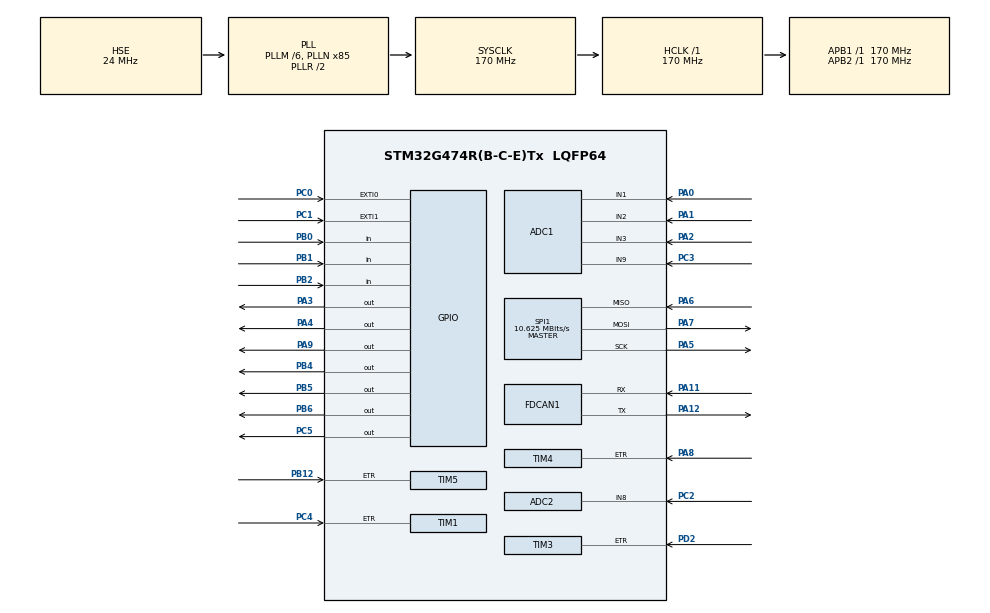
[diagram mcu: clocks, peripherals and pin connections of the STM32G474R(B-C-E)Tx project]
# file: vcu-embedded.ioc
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ADC1.Channel-0\#ChannelRegularConversion=ADC_CHANNEL_1
ADC1.NbrOfConversionFlag=1
ADC1.OffsetNumber-0\#ChannelRegularConversion=ADC_OFFSET_NONE
ADC1.Rank-0\#ChannelRegularConversion=1
ADC1.SamplingTime-0\#ChannelRegularConversion=ADC_SAMPLETIME_2CYCLES_5
ADC1.master=1
ADC2.Channel-1\#ChannelRegularConversion=ADC_CHANNEL_8
ADC2.NbrOfConversionFlag=1
ADC2.OffsetNumber-1\#ChannelRegularConversion=ADC_OFFSET_NONE
ADC2.Rank-1\#ChannelRegularConversion=1
ADC2.SamplingTime-1\#ChannelRegularConversion=ADC_SAMPLETIME_2CYCLES_5
FDCAN1.CalculateBaudRateNominal=500000
FDCAN1.CalculateTimeBitNominal=2000
FDCAN1.CalculateTimeQuantumNominal=83.33333333333333
FDCAN1.DataPrescaler=2
FDCAN1.DataTimeSeg1=12
FDCAN1.DataTimeSeg2=11
FDCAN1.NominalPrescaler=2
FDCAN1.NominalTimeSeg1=20
FDCAN1.NominalTimeSeg2=3
FREERTOS.Tasks01=gps,24,128,StartDefaultTask,Default,NULL,Dynamic,NULL,NULL
FREERTOS.configMAX_TASK_NAME_LEN=32
FREERTOS.configTOTAL_HEAP_SIZE=8000
Mcu.Family=STM32G4
Mcu.Name=STM32G474R(B-C-E)Tx
Mcu.Package=LQFP64
NVIC.PriorityGroup=NVIC_PRIORITYGROUP_4
NVIC.TIM6_DAC_IRQn=true\:15\:0\:false\:false\:true\:false\:false\:true\:true
NVIC.TimeBase=TIM6_DAC_IRQn
NVIC.TimeBaseIP=TIM6
PA0.Mode=IN1-Single-Ended
PA0.Signal=ADC1_IN1
PA1.Mode=IN2-Single-Ended
PA1.Signal=ADC1_IN2
PA11.Mode=FDCAN_Activate
PA11.Signal=FDCAN1_RX
PA12.Mode=FDCAN_Activate
PA12.Signal=FDCAN1_TX
PA13.Mode=Trace_Asynchronous_SW
PA13.Signal=SYS_JTMS-SWDIO
PA14.Mode=Trace_Asynchronous_SW
PA14.Signal=SYS_JTCK-SWCLK
PA2.Mode=IN3-Single-Ended
PA2.Signal=ADC1_IN3
PA3.Signal=GPIO_Output
PA4.Signal=GPIO_Output
PA5.Mode=Full_Duplex_Master
PA5.Signal=SPI1_SCK
PA6.Mode=Full_Duplex_Master
PA6.Signal=SPI1_MISO
PA7.Mode=Full_Duplex_Master
PA7.Signal=SPI1_MOSI
PA8.Signal=S_TIM4_ETR
PA9.Signal=GPIO_Output
PB0.Signal=GPIO_Input
PB1.Signal=GPIO_Input
PB12.Signal=S_TIM5_ETR
PB2.Signal=GPIO_Input
PB3.Mode=Trace_Asynchronous_SW
PB3.Signal=SYS_JTDO-SWO
PB4.Signal=GPIO_Output
PB5.Signal=GPIO_Output
PB6.Signal=GPIO_Output
PC0.Signal=GPXTI0
PC1.Signal=GPXTI1
PC14-OSC32_IN.Mode=LSE-External-Clock-Source
PC14-OSC32_IN.Signal=RCC_OSC32_IN
PC2.Mode=IN8-Single-Ended
PC2.Signal=ADC2_IN8
PC3.Mode=IN9-Single-Ended
PC3.Signal=ADC1_IN9
PC4.Signal=S_TIM1_ETR
PC5.Signal=GPIO_Output
PD2.Signal=S_TIM3_ETR
PF0-OSC_IN.Mode=HSE-External-Clock-Source
PF0-OSC_IN.Signal=RCC_OSC_IN
ProjectManager.HeapSize=0x200
ProjectManager.StackSize=0x400
ProjectManager.TargetToolchain=CMake
RCC.ADC12Freq_Value=170000000
RCC.ADC345Freq_Value=170000000
RCC.AHBFreq_Value=170000000
RCC.APB1Freq_Value=170000000
RCC.APB1TimFreq_Value=170000000
RCC.APB2Freq_Value=170000000
RCC.APB2TimFreq_Value=170000000
RCC.CortexFreq_Value=170000000
RCC.EXTERNAL_CLOCK_VALUE=12288000
RCC.EnbaleCSS=true
RCC.FDCANCLockSelection=RCC_FDCANCLKSOURCE_HSE
RCC.HCLKFreq_Value=170000000
RCC.HSE_VALUE=24000000
RCC.HSI48_VALUE=48000000
RCC.HSI_VALUE=16000000
RCC.LSE_VALUE=32768
RCC.PLLM=RCC_PLLM_DIV6
RCC.PLLN=85
RCC.PLLSourceVirtual=RCC_PLLSOURCE_HSE
RCC.SYSCLKFreq_VALUE=170000000
RCC.SYSCLKSource=RCC_SYSCLKSOURCE_PLLCLK
RCC.USBFreq_Value=170000000
RCC.VCOOutputFreq_Value=340000000
SH.S_TIM1_ETR.0=TIM1_ETR,TriggerSource_ETR
SH.S_TIM3_ETR.0=TIM3_ETR,TriggerSource_ETR
SH.S_TIM4_ETR.0=TIM4_ETR,TriggerSource_ETR
SH.S_TIM5_ETR.0=TIM5_ETR,TriggerSource_ETR
SPI1.BaudRatePrescaler=SPI_BAUDRATEPRESCALER_16
SPI1.CalculateBaudRate=10.625 MBits/s
SPI1.Direction=SPI_DIRECTION_2LINES
SPI1.Mode=SPI_MODE_MASTER
SPI1.TIMode=SPI_TIMODE_DISABLE
SPI1.VirtualType=VM_MASTER
VP_FREERTOS_VS_CMSIS_V2.Mode=CMSIS_V2
VP_SYS_VS_DBSignals.Mode=DisableDeadBatterySignals
VP_SYS_VS_tim6.Mode=TIM6
VP_TIM1_VS_ControllerModeClock.Mode=Clock Mode
VP_TIM3_VS_ControllerModeClock.Mode=Clock Mode
VP_TIM4_VS_ControllerModeClock.Mode=Clock Mode
VP_TIM5_VS_ControllerModeClock.Mode=Clock Mode
board=custom

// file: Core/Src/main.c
/* USER CODE BEGIN Header */
/**
  ******************************************************************************
  * @file           : main.c
  * @brief          : Main program body
  ******************************************************************************
  * @attention
  *
  * Copyright (c) 2025 STMicroelectronics.
  * All rights reserved.
  *
  * This software is licensed under terms that can be found in the LICENSE file
  * in the root directory of this software component.
  * If no LICENSE file comes with this software, it is provided AS-IS.
  *
  ******************************************************************************
  */
/* USER CODE END Header */
#include "main.h"
#include "cmsis_os.h"
#include "stm32g4xx_hal_gpio.h"

ADC_HandleTypeDef hadc1;
ADC_HandleTypeDef hadc2;

FDCAN_HandleTypeDef hfdcan1;

FDCAN_TxHeaderTypeDef txHeader;
uint8_t txData[] = {0x01,0x02,0x03,0x04,0x05,0x06,0x07,0x08}; // Tx Buffer

SPI_HandleTypeDef hspi1;

TIM_HandleTypeDef htim1;
TIM_HandleTypeDef htim3;
TIM_HandleTypeDef htim4;
TIM_HandleTypeDef htim5;

/* Definitions for gps */
osThreadId_t gpsHandle;
const osThreadAttr_t gps_attributes = {
  .name = "gps",
  .priority = (osPriority_t) osPriorityNormal,
  .stack_size = 128 * 4
};

void SystemClock_Config(void);
static void MX_GPIO_Init(void);
static void MX_ADC1_Init(void);
static void MX_ADC2_Init(void);
static void MX_FDCAN1_Init(void);
static void MX_SPI1_Init(void);
static void MX_TIM1_Init(void);
static void MX_TIM3_Init(void);
static void MX_TIM4_Init(void);
static void MX_TIM5_Init(void);
void StartDefaultTask(void *argument);
static void FDCAN_Config(void);

int main(void)
{

  /* MCU Configuration--------------------------------------------------------*/

  /* Reset of all peripherals, Initializes the Flash interface and the Systick. */
  HAL_Init();

  /* Configure the system clock */
  SystemClock_Config();

  /* Initialize all configured peripherals */
  MX_GPIO_Init();
  MX_ADC1_Init();
  MX_ADC2_Init();
  MX_FDCAN1_Init();
  MX_SPI1_Init();
  MX_TIM1_Init();
  MX_TIM3_Init();
  MX_TIM4_Init();
  MX_TIM5_Init();

  /* Init scheduler */
  osKernelInitialize();

  /* Create the thread(s) */
  /* creation of gps */
  gpsHandle = osThreadNew(StartDefaultTask, NULL, &gps_attributes);

  /* Start scheduler */
  osKernelStart();

  /* We should never get here as control is now taken by the scheduler */

  /* Infinite loop */
  while (1)
  {

  }
}

void SystemClock_Config(void)
{
  RCC_OscInitTypeDef RCC_OscInitStruct = {0};
  RCC_ClkInitTypeDef RCC_ClkInitStruct = {0};

  /** Configure the main internal regulator output voltage
  */
  HAL_PWREx_ControlVoltageScaling(PWR_REGULATOR_VOLTAGE_SCALE1_BOOST);

  /** Initializes the RCC Oscillators according to the specified parameters
  * in the RCC_OscInitTypeDef structure.
  */
  RCC_OscInitStruct.OscillatorType = RCC_OSCILLATORTYPE_HSE;
  RCC_OscInitStruct.HSEState = RCC_HSE_BYPASS;
  RCC_OscInitStruct.PLL.PLLState = RCC_PLL_ON;
  RCC_OscInitStruct.PLL.PLLSource = RCC_PLLSOURCE_HSE;
  RCC_OscInitStruct.PLL.PLLM = RCC_PLLM_DIV6;
  RCC_OscInitStruct.PLL.PLLN = 85;
  RCC_OscInitStruct.PLL.PLLP = RCC_PLLP_DIV2;
  RCC_OscInitStruct.PLL.PLLQ = RCC_PLLQ_DIV2;
  RCC_OscInitStruct.PLL.PLLR = RCC_PLLR_DIV2;
  if (HAL_RCC_OscConfig(&RCC_OscInitStruct) != HAL_OK)
  {
    Error_Handler();
  }

  /** Initializes the CPU, AHB and APB buses clocks
  */
  RCC_ClkInitStruct.ClockType = RCC_CLOCKTYPE_HCLK|RCC_CLOCKTYPE_SYSCLK
                              |RCC_CLOCKTYPE_PCLK1|RCC_CLOCKTYPE_PCLK2;
  RCC_ClkInitStruct.SYSCLKSource = RCC_SYSCLKSOURCE_PLLCLK;
  RCC_ClkInitStruct.AHBCLKDivider = RCC_SYSCLK_DIV1;
  RCC_ClkInitStruct.APB1CLKDivider = RCC_HCLK_DIV1;
  RCC_ClkInitStruct.APB2CLKDivider = RCC_HCLK_DIV1;

  if (HAL_RCC_ClockConfig(&RCC_ClkInitStruct, FLASH_LATENCY_4) != HAL_OK)
  {
    Error_Handler();
  }

  /** Enables the Clock Security System
  */
  HAL_RCC_EnableCSS();
}

static void MX_ADC1_Init(void)
{

  ADC_MultiModeTypeDef multimode = {0};
  ADC_ChannelConfTypeDef sConfig = {0};

  /** Common config
  */
  hadc1.Instance = ADC1;
  hadc1.Init.ClockPrescaler = ADC_CLOCK_SYNC_PCLK_DIV4;
  hadc1.Init.Resolution = ADC_RESOLUTION_12B;
  hadc1.Init.DataAlign = ADC_DATAALIGN_RIGHT;
  hadc1.Init.GainCompensation = 0;
  hadc1.Init.ScanConvMode = ADC_SCAN_DISABLE;
  hadc1.Init.EOCSelection = ADC_EOC_SINGLE_CONV;
  hadc1.Init.LowPowerAutoWait = DISABLE;
  hadc1.Init.ContinuousConvMode = DISABLE;
  hadc1.Init.NbrOfConversion = 1;
  hadc1.Init.DiscontinuousConvMode = DISABLE;
  hadc1.Init.ExternalTrigConv = ADC_SOFTWARE_START;
  hadc1.Init.ExternalTrigConvEdge = ADC_EXTERNALTRIGCONVEDGE_NONE;
  hadc1.Init.DMAContinuousRequests = DISABLE;
  hadc1.Init.Overrun = ADC_OVR_DATA_PRESERVED;
  hadc1.Init.OversamplingMode = DISABLE;
  if (HAL_ADC_Init(&hadc1) != HAL_OK)
  {
    Error_Handler();
  }

  /** Configure the ADC multi-mode
  */
  multimode.Mode = ADC_MODE_INDEPENDENT;
  if (HAL_ADCEx_MultiModeConfigChannel(&hadc1, &multimode) != HAL_OK)
  {
    Error_Handler();
  }

  /** Configure Regular Channel
  */
  sConfig.Channel = ADC_CHANNEL_1;
  sConfig.Rank = ADC_REGULAR_RANK_1;
  sConfig.SamplingTime = ADC_SAMPLETIME_2CYCLES_5;
  sConfig.SingleDiff = ADC_SINGLE_ENDED;
  sConfig.OffsetNumber = ADC_OFFSET_NONE;
  sConfig.Offset = 0;
  if (HAL_ADC_ConfigChannel(&hadc1, &sConfig) != HAL_OK)
  {
    Error_Handler();
  }

}

static void MX_ADC2_Init(void)
{

  ADC_ChannelConfTypeDef sConfig = {0};

  /** Common config
  */
  hadc2.Instance = ADC2;
  hadc2.Init.ClockPrescaler = ADC_CLOCK_SYNC_PCLK_DIV4;
  hadc2.Init.Resolution = ADC_RESOLUTION_12B;
  hadc2.Init.DataAlign = ADC_DATAALIGN_RIGHT;
  hadc2.Init.GainCompensation = 0;
  hadc2.Init.ScanConvMode = ADC_SCAN_DISABLE;
  hadc2.Init.EOCSelection = ADC_EOC_SINGLE_CONV;
  hadc2.Init.LowPowerAutoWait = DISABLE;
  hadc2.Init.ContinuousConvMode = DISABLE;
  hadc2.Init.NbrOfConversion = 1;
  hadc2.Init.DiscontinuousConvMode = DISABLE;
  hadc2.Init.ExternalTrigConv = ADC_SOFTWARE_START;
  hadc2.Init.ExternalTrigConvEdge = ADC_EXTERNALTRIGCONVEDGE_NONE;
  hadc2.Init.DMAContinuousRequests = DISABLE;
  hadc2.Init.Overrun = ADC_OVR_DATA_PRESERVED;
  hadc2.Init.OversamplingMode = DISABLE;
  if (HAL_ADC_Init(&hadc2) != HAL_OK)
  {
    Error_Handler();
  }

  /** Configure Regular Channel
  */
  sConfig.Channel = ADC_CHANNEL_8;
  sConfig.Rank = ADC_REGULAR_RANK_1;
  sConfig.SamplingTime = ADC_SAMPLETIME_2CYCLES_5;
  sConfig.SingleDiff = ADC_SINGLE_ENDED;
  sConfig.OffsetNumber = ADC_OFFSET_NONE;
  sConfig.Offset = 0;
  if (HAL_ADC_ConfigChannel(&hadc2, &sConfig) != HAL_OK)
  {
    Error_Handler();
  }

}

static void MX_FDCAN1_Init(void)
{

  hfdcan1.Instance = FDCAN1;
  hfdcan1.Init.ClockDivider = FDCAN_CLOCK_DIV1;
  hfdcan1.Init.FrameFormat = FDCAN_FRAME_CLASSIC;
  hfdcan1.Init.Mode = FDCAN_MODE_NORMAL;
  hfdcan1.Init.AutoRetransmission = DISABLE;
  hfdcan1.Init.TransmitPause = DISABLE;
  hfdcan1.Init.ProtocolException = DISABLE;
  hfdcan1.Init.NominalPrescaler = 2;
  hfdcan1.Init.NominalSyncJumpWidth = 1;
  hfdcan1.Init.NominalTimeSeg1 = 20;
  hfdcan1.Init.NominalTimeSeg2 = 3;
  hfdcan1.Init.DataPrescaler = 2;
  hfdcan1.Init.DataSyncJumpWidth = 1;
  hfdcan1.Init.DataTimeSeg1 = 12;
  hfdcan1.Init.DataTimeSeg2 = 11;
  hfdcan1.Init.StdFiltersNbr = 0;
  hfdcan1.Init.ExtFiltersNbr = 0;
  hfdcan1.Init.TxFifoQueueMode = FDCAN_TX_FIFO_OPERATION;
  if (HAL_FDCAN_Init(&hfdcan1) != HAL_OK)
  {
    Error_Handler();
  }

}

static void MX_SPI1_Init(void)
{

  /* SPI1 parameter configuration*/
  hspi1.Instance = SPI1;
  hspi1.Init.Mode = SPI_MODE_MASTER;
  hspi1.Init.Direction = SPI_DIRECTION_2LINES;
  hspi1.Init.DataSize = SPI_DATASIZE_4BIT;
  hspi1.Init.CLKPolarity = SPI_POLARITY_LOW;
  hspi1.Init.CLKPhase = SPI_PHASE_1EDGE;
  hspi1.Init.NSS = SPI_NSS_SOFT;
  hspi1.Init.BaudRatePrescaler = SPI_BAUDRATEPRESCALER_16;
  hspi1.Init.FirstBit = SPI_FIRSTBIT_MSB;
  hspi1.Init.TIMode = SPI_TIMODE_DISABLE;
  hspi1.Init.CRCCalculation = SPI_CRCCALCULATION_DISABLE;
  hspi1.Init.CRCPolynomial = 7;
  hspi1.Init.CRCLength = SPI_CRC_LENGTH_DATASIZE;
  hspi1.Init.NSSPMode = SPI_NSS_PULSE_ENABLE;
  if (HAL_SPI_Init(&hspi1) != HAL_OK)
  {
    Error_Handler();
  }

}

static void MX_TIM1_Init(void)
{

  TIM_SlaveConfigTypeDef sSlaveConfig = {0};
  TIM_MasterConfigTypeDef sMasterConfig = {0};

  htim1.Instance = TIM1;
  htim1.Init.Prescaler = 0;
  htim1.Init.CounterMode = TIM_COUNTERMODE_UP;
  htim1.Init.Period = 65535;
  htim1.Init.ClockDivision = TIM_CLOCKDIVISION_DIV1;
  htim1.Init.RepetitionCounter = 0;
  htim1.Init.AutoReloadPreload = TIM_AUTORELOAD_PRELOAD_DISABLE;
  if (HAL_TIM_Base_Init(&htim1) != HAL_OK)
  {
    Error_Handler();
  }
  sSlaveConfig.SlaveMode = TIM_SLAVEMODE_EXTERNAL1;
  sSlaveConfig.InputTrigger = TIM_TS_ETRF;
  sSlaveConfig.TriggerPolarity = TIM_TRIGGERPOLARITY_NONINVERTED;
  sSlaveConfig.TriggerPrescaler = TIM_TRIGGERPRESCALER_DIV1;
  sSlaveConfig.TriggerFilter = 0;
  if (HAL_TIM_SlaveConfigSynchro(&htim1, &sSlaveConfig) != HAL_OK)
  {
    Error_Handler();
  }
  sMasterConfig.MasterOutputTrigger = TIM_TRGO_RESET;
  sMasterConfig.MasterOutputTrigger2 = TIM_TRGO2_RESET;
  sMasterConfig.MasterSlaveMode = TIM_MASTERSLAVEMODE_DISABLE;
  if (HAL_TIMEx_MasterConfigSynchronization(&htim1, &sMasterConfig) != HAL_OK)
  {
    Error_Handler();
  }

}

static void MX_TIM3_Init(void)
{

  TIM_SlaveConfigTypeDef sSlaveConfig = {0};
  TIM_MasterConfigTypeDef sMasterConfig = {0};

  htim3.Instance = TIM3;
  htim3.Init.Prescaler = 0;
  htim3.Init.CounterMode = TIM_COUNTERMODE_UP;
  htim3.Init.Period = 65535;
  htim3.Init.ClockDivision = TIM_CLOCKDIVISION_DIV1;
  htim3.Init.AutoReloadPreload = TIM_AUTORELOAD_PRELOAD_DISABLE;
  if (HAL_TIM_Base_Init(&htim3) != HAL_OK)
  {
    Error_Handler();
  }
  sSlaveConfig.SlaveMode = TIM_SLAVEMODE_EXTERNAL1;
  sSlaveConfig.InputTrigger = TIM_TS_ETRF;
  sSlaveConfig.TriggerPolarity = TIM_TRIGGERPOLARITY_NONINVERTED;
  sSlaveConfig.TriggerPrescaler = TIM_TRIGGERPRESCALER_DIV1;
  sSlaveConfig.TriggerFilter = 0;
  if (HAL_TIM_SlaveConfigSynchro(&htim3, &sSlaveConfig) != HAL_OK)
  {
    Error_Handler();
  }
  sMasterConfig.MasterOutputTrigger = TIM_TRGO_RESET;
  sMasterConfig.MasterSlaveMode = TIM_MASTERSLAVEMODE_DISABLE;
  if (HAL_TIMEx_MasterConfigSynchronization(&htim3, &sMasterConfig) != HAL_OK)
  {
    Error_Handler();
  }

}

static void MX_TIM4_Init(void)
{

  TIM_SlaveConfigTypeDef sSlaveConfig = {0};
  TIM_MasterConfigTypeDef sMasterConfig = {0};

  htim4.Instance = TIM4;
  htim4.Init.Prescaler = 0;
  htim4.Init.CounterMode = TIM_COUNTERMODE_UP;
  htim4.Init.Period = 65535;
  htim4.Init.ClockDivision = TIM_CLOCKDIVISION_DIV1;
  htim4.Init.AutoReloadPreload = TIM_AUTORELOAD_PRELOAD_DISABLE;
  if (HAL_TIM_Base_Init(&htim4) != HAL_OK)
  {
    Error_Handler();
  }
  sSlaveConfig.SlaveMode = TIM_SLAVEMODE_EXTERNAL1;
  sSlaveConfig.InputTrigger = TIM_TS_ETRF;
  sSlaveConfig.TriggerPolarity = TIM_TRIGGERPOLARITY_NONINVERTED;
  sSlaveConfig.TriggerPrescaler = TIM_TRIGGERPRESCALER_DIV1;
  sSlaveConfig.TriggerFilter = 0;
  if (HAL_TIM_SlaveConfigSynchro(&htim4, &sSlaveConfig) != HAL_OK)
  {
    Error_Handler();
  }
  sMasterConfig.MasterOutputTrigger = TIM_TRGO_RESET;
  sMasterConfig.MasterSlaveMode = TIM_MASTERSLAVEMODE_DISABLE;
  if (HAL_TIMEx_MasterConfigSynchronization(&htim4, &sMasterConfig) != HAL_OK)
  {
    Error_Handler();
  }

}

static void MX_TIM5_Init(void)
{

  TIM_SlaveConfigTypeDef sSlaveConfig = {0};
  TIM_MasterConfigTypeDef sMasterConfig = {0};

  htim5.Instance = TIM5;
  htim5.Init.Prescaler = 0;
  htim5.Init.CounterMode = TIM_COUNTERMODE_UP;
  htim5.Init.Period = 4294967295;
  htim5.Init.ClockDivision = TIM_CLOCKDIVISION_DIV1;
  htim5.Init.AutoReloadPreload = TIM_AUTORELOAD_PRELOAD_DISABLE;
  if (HAL_TIM_Base_Init(&htim5) != HAL_OK)
  {
    Error_Handler();
  }
  sSlaveConfig.SlaveMode = TIM_SLAVEMODE_EXTERNAL1;
  sSlaveConfig.InputTrigger = TIM_TS_ETRF;
  sSlaveConfig.TriggerPolarity = TIM_TRIGGERPOLARITY_NONINVERTED;
  sSlaveConfig.TriggerPrescaler = TIM_TRIGGERPRESCALER_DIV1;
  sSlaveConfig.TriggerFilter = 0;
  if (HAL_TIM_SlaveConfigSynchro(&htim5, &sSlaveConfig) != HAL_OK)
  {
    Error_Handler();
  }
  sMasterConfig.MasterOutputTrigger = TIM_TRGO_RESET;
  sMasterConfig.MasterSlaveMode = TIM_MASTERSLAVEMODE_DISABLE;
  if (HAL_TIMEx_MasterConfigSynchronization(&htim5, &sMasterConfig) != HAL_OK)
  {
    Error_Handler();
  }

}

static void MX_GPIO_Init(void)
{
  GPIO_InitTypeDef GPIO_InitStruct = {0};

  /* GPIO Ports Clock Enable */
  __HAL_RCC_GPIOC_CLK_ENABLE();
  __HAL_RCC_GPIOF_CLK_ENABLE();
  __HAL_RCC_GPIOA_CLK_ENABLE();
  __HAL_RCC_GPIOB_CLK_ENABLE();
  __HAL_RCC_GPIOD_CLK_ENABLE();

  /*Configure GPIO pin Output Level */
  HAL_GPIO_WritePin(GPIOA, GPIO_PIN_3|GPIO_PIN_4|GPIO_PIN_9, GPIO_PIN_RESET);

  /*Configure GPIO pin Output Level */
  HAL_GPIO_WritePin(GPIOC, GPIO_PIN_5, GPIO_PIN_RESET);

  /*Configure GPIO pin Output Level */
  HAL_GPIO_WritePin(GPIOB, GPIO_PIN_4|GPIO_PIN_5|GPIO_PIN_6, GPIO_PIN_RESET);

  /*Configure GPIO pins : PC0 PC1 */
  GPIO_InitStruct.Pin = GPIO_PIN_0|GPIO_PIN_1;
  GPIO_InitStruct.Mode = GPIO_MODE_IT_RISING;
  GPIO_InitStruct.Pull = GPIO_NOPULL;
  HAL_GPIO_Init(GPIOC, &GPIO_InitStruct);

  /*Configure GPIO pins : PA3 PA4 PA9 */
  GPIO_InitStruct.Pin = GPIO_PIN_3|GPIO_PIN_4|GPIO_PIN_9;
  GPIO_InitStruct.Mode = GPIO_MODE_OUTPUT_PP;
  GPIO_InitStruct.Pull = GPIO_NOPULL;
  GPIO_InitStruct.Speed = GPIO_SPEED_FREQ_LOW;
  HAL_GPIO_Init(GPIOA, &GPIO_InitStruct);

  /*Configure GPIO pin : PC5 */
  GPIO_InitStruct.Pin = GPIO_PIN_5;
  GPIO_InitStruct.Mode = GPIO_MODE_OUTPUT_PP;
  GPIO_InitStruct.Pull = GPIO_NOPULL;
  GPIO_InitStruct.Speed = GPIO_SPEED_FREQ_LOW;
  HAL_GPIO_Init(GPIOC, &GPIO_InitStruct);

  /*Configure GPIO pins : PB0 PB1 PB2 */
  GPIO_InitStruct.Pin = GPIO_PIN_0|GPIO_PIN_1|GPIO_PIN_2;
  GPIO_InitStruct.Mode = GPIO_MODE_INPUT;
  GPIO_InitStruct.Pull = GPIO_NOPULL;
  HAL_GPIO_Init(GPIOB, &GPIO_InitStruct);

  /*Configure GPIO pins : PB4 PB5 PB6 */
  GPIO_InitStruct.Pin = GPIO_PIN_4|GPIO_PIN_5|GPIO_PIN_6;
  GPIO_InitStruct.Mode = GPIO_MODE_OUTPUT_PP;
  GPIO_InitStruct.Pull = GPIO_NOPULL;
  GPIO_InitStruct.Speed = GPIO_SPEED_FREQ_LOW;
  HAL_GPIO_Init(GPIOB, &GPIO_InitStruct);

}

void StartDefaultTask(void *argument)
{
  /* USER CODE BEGIN 5 */
  /* Infinite loop */
  FDCAN_Config();
  HAL_FDCAN_Start(&hfdcan1); //Initialize CAN Bus

  while(1)
  {
    // if (HAL_FDCAN_AddMessageToTxFifoQ(&hfdcan1, &txHeader, txData) != HAL_OK) {
		// 			Error_Handler();
		// }
    // HAL_Delay(10);

    // Reverse relay
    if(HAL_GPIO_ReadPin(GPIOB, GPIO_PIN_0)){
      HAL_GPIO_WritePin(GPIOB, GPIO_PIN_4, GPIO_PIN_SET);
    }
    else {
      HAL_GPIO_WritePin(GPIOB, GPIO_PIN_4, GPIO_PIN_RESET);
    }

    // Emergency shutdown relay
    //HAL_GPIO_TogglePin(GPIOB, GPIO_PIN_5);

    // Debug LED
    HAL_GPIO_TogglePin(GPIOB, GPIO_PIN_6);

    osDelay(pdMS_TO_TICKS(100));
  }
  /* USER CODE END 5 */
}

static void FDCAN_Config(void)
{
  FDCAN_FilterTypeDef sFilterConfig;

  /* Configure Rx filter */
  sFilterConfig.IdType = FDCAN_STANDARD_ID;
  sFilterConfig.FilterIndex = 0;
  sFilterConfig.FilterType = FDCAN_FILTER_RANGE;
  sFilterConfig.FilterConfig = FDCAN_FILTER_TO_RXFIFO0;
  sFilterConfig.FilterID1 = 0x321;
  sFilterConfig.FilterID2 = 0x7FF;
  if (HAL_FDCAN_ConfigFilter(&hfdcan1, &sFilterConfig) != HAL_OK)
  {
    Error_Handler();
  }

  /* Start the FDCAN module */
  if (HAL_FDCAN_Start(&hfdcan1) != HAL_OK)
  {
    Error_Handler();
  }

  if (HAL_FDCAN_ActivateNotification(&hfdcan1, FDCAN_IT_RX_FIFO0_NEW_MESSAGE, 0) != HAL_OK)
  {
    Error_Handler();
  }

  /* Prepare Tx Header */
  txHeader.Identifier = 0x321;
  txHeader.IdType = FDCAN_STANDARD_ID;
  txHeader.TxFrameType = FDCAN_DATA_FRAME;
  txHeader.DataLength = FDCAN_DLC_BYTES_2;
  txHeader.ErrorStateIndicator = FDCAN_ESI_PASSIVE;
  txHeader.BitRateSwitch = FDCAN_BRS_OFF;
  txHeader.FDFormat = FDCAN_CLASSIC_CAN;
  txHeader.TxEventFifoControl = FDCAN_NO_TX_EVENTS;
  txHeader.MessageMarker = 0;
}

void HAL_TIM_PeriodElapsedCallback(TIM_HandleTypeDef *htim)
{
  if (htim->Instance == TIM6)
  {
    HAL_IncTick();
  }
}

void Error_Handler(void)
{
  __disable_irq();
  while (1)
  {
  }
}
